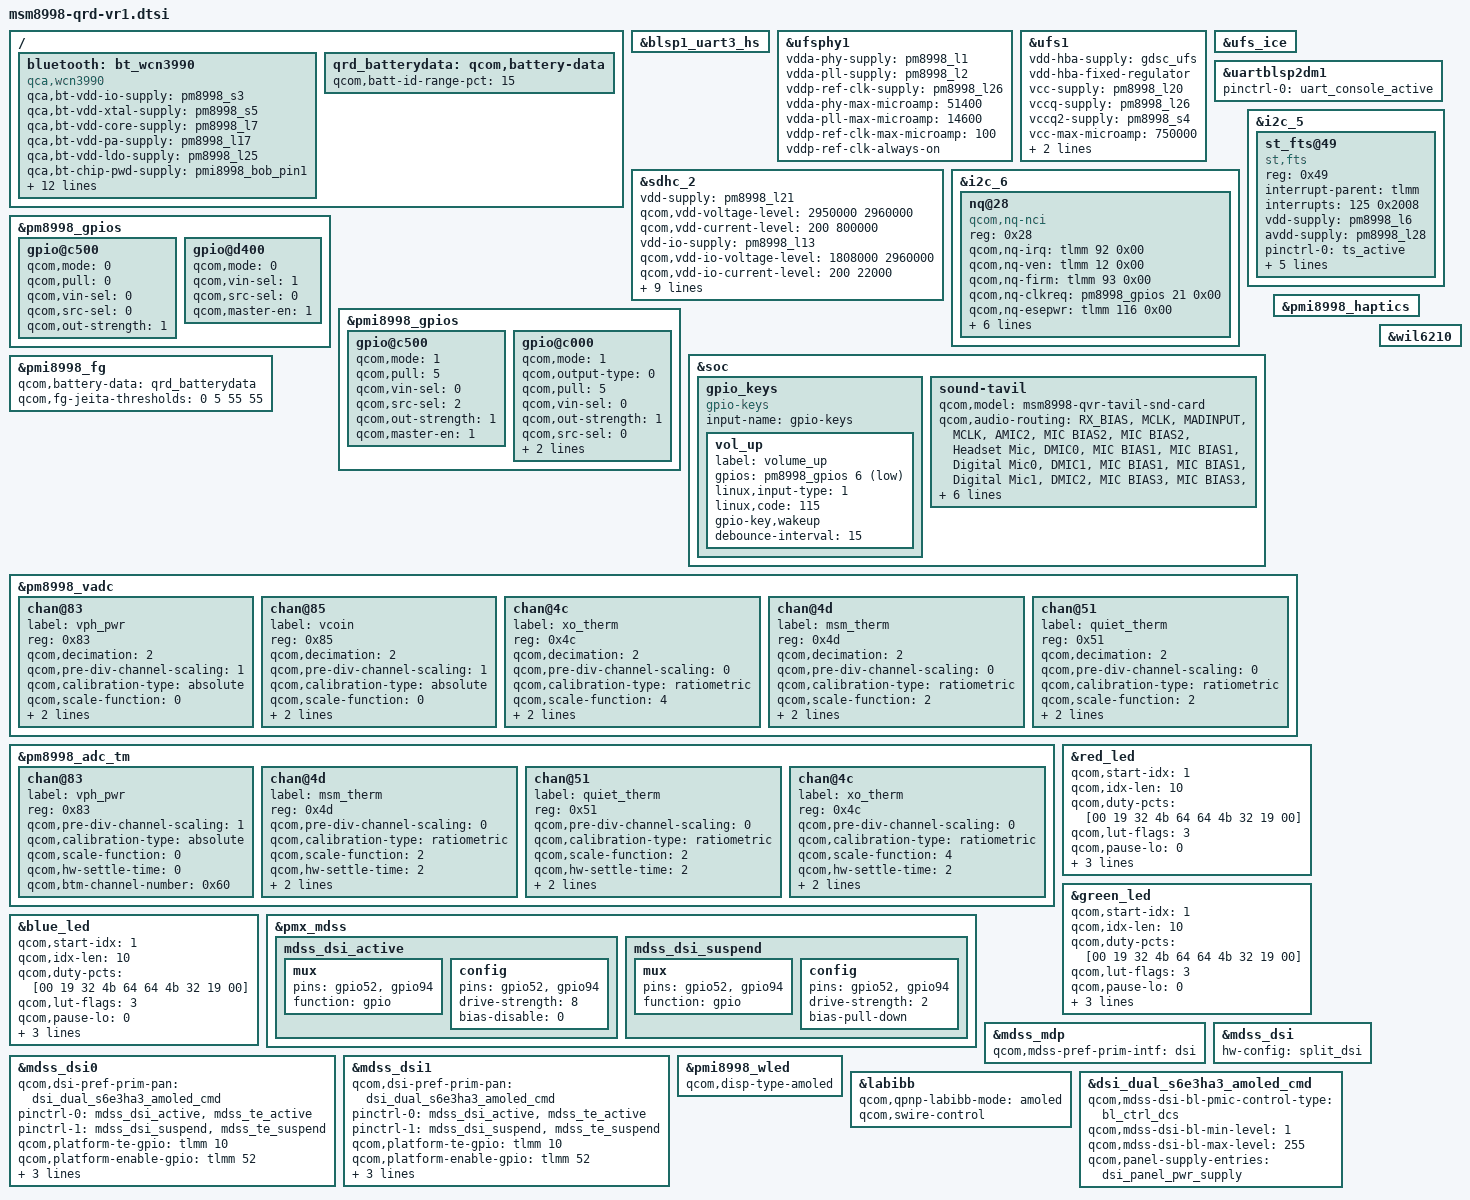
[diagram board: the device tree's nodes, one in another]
/* Copyright (c) 2016-2017, The Linux Foundation. All rights reserved.
 *
 * This program is free software; you can redistribute it and/or modify
 * it under the terms of the GNU General Public License version 2 and
 * only version 2 as published by the Free Software Foundation.
 *
 * This program is distributed in the hope that it will be useful,
 * but WITHOUT ANY WARRANTY; without even the implied warranty of
 * MERCHANTABILITY or FITNESS FOR A PARTICULAR PURPOSE.  See the
 * GNU General Public License for more details.
 */

#include <dt-bindings/interrupt-controller/irq.h>
#include "msm8998-pinctrl.dtsi"
#include "msm8998-camera-sensor-qrd-vr1.dtsi"

/ {
	bluetooth: bt_wcn3990 {
		compatible = "qca,wcn3990";
		qca,bt-vdd-io-supply = <&pm8998_s3>;
		qca,bt-vdd-xtal-supply = <&pm8998_s5>;
		qca,bt-vdd-core-supply = <&pm8998_l7>;
		qca,bt-vdd-pa-supply = <&pm8998_l17>;
		qca,bt-vdd-ldo-supply = <&pm8998_l25>;
		qca,bt-chip-pwd-supply = <&pmi8998_bob_pin1>;
		clocks = <&clock_gcc clk_rf_clk2_pin>;
		clock-names = "rf_clk2";

		qca,bt-vdd-io-voltage-level = <1352000 1352000>;
		qca,bt-vdd-xtal-voltage-level = <2040000 2040000>;
		qca,bt-vdd-core-voltage-level = <1800000 1800000>;
		qca,bt-vdd-pa-voltage-level = <1304000 1304000>;
		qca,bt-vdd-ldo-voltage-level = <3312000 3312000>;
		qca,bt-chip-pwd-voltage-level = <3600000 3600000>;

		qca,bt-vdd-io-current-level = <1>; /* LPM/PFM */
		qca,bt-vdd-xtal-current-level = <1>; /* LPM/PFM */
		qca,bt-vdd-core-current-level = <1>; /* LPM/PFM */
		qca,bt-vdd-pa-current-level = <1>; /* LPM/PFM */
		qca,bt-vdd-ldo-current-level = <1>; /* LPM/PFM */
	};
};

&blsp1_uart3_hs {
	status = "ok";
};

&ufsphy1 {
	vdda-phy-supply = <&pm8998_l1>;
	vdda-pll-supply = <&pm8998_l2>;
	vddp-ref-clk-supply = <&pm8998_l26>;
	vdda-phy-max-microamp = <51400>;
	vdda-pll-max-microamp = <14600>;
	vddp-ref-clk-max-microamp = <100>;
	vddp-ref-clk-always-on;
	status = "ok";
};

&ufs1 {
	vdd-hba-supply = <&gdsc_ufs>;
	vdd-hba-fixed-regulator;
	vcc-supply = <&pm8998_l20>;
	vccq-supply = <&pm8998_l26>;
	vccq2-supply = <&pm8998_s4>;
	vcc-max-microamp = <750000>;
	vccq-max-microamp = <560000>;
	vccq2-max-microamp = <750000>;
	status = "ok";
};

&ufs_ice {
	status = "ok";
};

&sdhc_2 {
	vdd-supply = <&pm8998_l21>;
	qcom,vdd-voltage-level = <2950000 2960000>;
	qcom,vdd-current-level = <200 800000>;

	vdd-io-supply = <&pm8998_l13>;
	qcom,vdd-io-voltage-level = <1808000 2960000>;
	qcom,vdd-io-current-level = <200 22000>;

	pinctrl-names = "active", "sleep";
	pinctrl-0 = <&sdc2_clk_on  &sdc2_cmd_on &sdc2_data_on &sdc2_cd_on>;
	pinctrl-1 = <&sdc2_clk_off &sdc2_cmd_off &sdc2_data_off &sdc2_cd_off>;

	qcom,clk-rates = <400000 20000000 25000000
				50000000 100000000 200000000>;
	qcom,bus-speed-mode = "SDR12", "SDR25", "SDR50", "DDR50", "SDR104";

	cd-gpios = <&tlmm 95 0x0>;

	status = "ok";
};

&uartblsp2dm1 {
	status = "ok";
	pinctrl-names = "default";
	pinctrl-0 = <&uart_console_active>;
};

&i2c_6 { /* BLSP1 QUP6 (NFC) */
	status = "okay";
	nq@28 {
		compatible = "qcom,nq-nci";
		reg = <0x28>;
		qcom,nq-irq = <&tlmm 92 0x00>;
		qcom,nq-ven = <&tlmm 12 0x00>;
		qcom,nq-firm = <&tlmm 93 0x00>;
		qcom,nq-clkreq = <&pm8998_gpios 21 0x00>;
		qcom,nq-esepwr = <&tlmm 116 0x00>;
		interrupt-parent = <&tlmm>;
		qcom,clk-src = "BBCLK3";
		interrupts = <92 0>;
		interrupt-names = "nfc_irq";
		pinctrl-names = "nfc_active", "nfc_suspend";
		pinctrl-0 = <&nfc_int_active &nfc_enable_active>;
		pinctrl-1 = <&nfc_int_suspend &nfc_enable_suspend>;
		clocks = <&clock_gcc clk_ln_bb_clk3_pin>;
		clock-names = "ref_clk";
	};
};

&pm8998_gpios {
	/* GPIO 6 for Vol+ Key */
	gpio@c500 {
		status = "okay";
		qcom,mode = <0>;
		qcom,pull = <0>;
		qcom,vin-sel = <0>;
		qcom,src-sel = <0>;
		qcom,out-strength = <1>;
	};

	/* GPIO 21 (NFC_CLK_REQ) */
	gpio@d400 {
		qcom,mode = <0>;
		qcom,vin-sel = <1>;
		qcom,src-sel = <0>;
		qcom,master-en = <1>;
		status = "okay";
	};
};

&pmi8998_gpios {
	/* GPIO 6 for the internal QNOVO discharge FET control signal */
	gpio@c500 {
		status = "okay";
		qcom,mode = <1>;
		qcom,pull = <5>;
		qcom,vin-sel = <0>;
		qcom,src-sel = <2>;
		qcom,out-strength = <1>;
		qcom,master-en = <1>;
	};
};

&i2c_5 {
	status = "okay";
	st_fts@49 {
		compatible = "st,fts";
		reg = <0x49>;
		interrupt-parent = <&tlmm>;
		interrupts = <125 0x2008>;
		vdd-supply = <&pm8998_l6>;
		avdd-supply = <&pm8998_l28>;
		pinctrl-names = "pmx_ts_active", "pmx_ts_suspend";
		pinctrl-0 = <&ts_active>;
		pinctrl-1 = <&ts_int_suspend &ts_reset_suspend>;
		st,irq-gpio = <&tlmm 125 0x2008>;
		st,reset-gpio = <&tlmm 89 0x00>;
		st,regulator_dvdd = "vdd";
		st,regulator_avdd = "avdd";
	};
};

&soc {
	gpio_keys {
		compatible = "gpio-keys";
		input-name = "gpio-keys";
		status = "okay";

		vol_up {
			label = "volume_up";
			gpios = <&pm8998_gpios 6 0x1>;
			linux,input-type = <1>;
			linux,code = <115>;
			gpio-key,wakeup;
			debounce-interval = <15>;
		};
	};

	sound-tavil {
		qcom,model = "msm8998-qvr-tavil-snd-card";
		qcom,audio-routing =
			"RX_BIAS", "MCLK",
			"MADINPUT", "MCLK",
			"AMIC2", "MIC BIAS2",
			"MIC BIAS2", "Headset Mic",
			"DMIC0", "MIC BIAS1",
			"MIC BIAS1", "Digital Mic0",
			"DMIC1", "MIC BIAS1",
			"MIC BIAS1", "Digital Mic1",
			"DMIC2", "MIC BIAS3",
			"MIC BIAS3", "Digital Mic2",
			"DMIC4", "MIC BIAS4",
			"MIC BIAS4", "Digital Mic4",
			"SpkrLeft IN", "SPK1 OUT";

		qcom,msm-mbhc-hphl-swh = <1>;
		/delete-property/ qcom,us-euro-gpios;
		/delete-property/ qcom,hph-en0-gpio;
		/delete-property/ qcom,hph-en0-gpio;

		qcom,wsa-max-devs = <1>;
		qcom,wsa-devs = <&wsa881x_0211>, <&wsa881x_0213>;
		qcom,wsa-aux-dev-prefix = "SpkrLeft", "SpkrLeft";
	};
};

/{
	qrd_batterydata: qcom,battery-data {
		qcom,batt-id-range-pct = <15>;
		#include "fg-gen3-batterydata-qrd-skuk-4v4-3000mah.dtsi"
	};
};

&pmi8998_fg {
	qcom,battery-data = <&qrd_batterydata>;
	qcom,fg-jeita-thresholds = <0 5 55 55>;
};

&pmi8998_haptics {
	status = "okay";
};

&pm8998_vadc {
	chan@83 {
		label = "vph_pwr";
		reg = <0x83>;
		qcom,decimation = <2>;
		qcom,pre-div-channel-scaling = <1>;
		qcom,calibration-type = "absolute";
		qcom,scale-function = <0>;
		qcom,hw-settle-time = <0>;
		qcom,fast-avg-setup = <0>;
	};

	chan@85 {
		label = "vcoin";
		reg = <0x85>;
		qcom,decimation = <2>;
		qcom,pre-div-channel-scaling = <1>;
		qcom,calibration-type = "absolute";
		qcom,scale-function = <0>;
		qcom,hw-settle-time = <0>;
		qcom,fast-avg-setup = <0>;
	};

	chan@4c {
		label = "xo_therm";
		reg = <0x4c>;
		qcom,decimation = <2>;
		qcom,pre-div-channel-scaling = <0>;
		qcom,calibration-type = "ratiometric";
		qcom,scale-function = <4>;
		qcom,hw-settle-time = <2>;
		qcom,fast-avg-setup = <0>;
	};

	chan@4d {
		label = "msm_therm";
		reg = <0x4d>;
		qcom,decimation = <2>;
		qcom,pre-div-channel-scaling = <0>;
		qcom,calibration-type = "ratiometric";
		qcom,scale-function = <2>;
		qcom,hw-settle-time = <2>;
		qcom,fast-avg-setup = <0>;
	};

	chan@51 {
		label = "quiet_therm";
		reg = <0x51>;
		qcom,decimation = <2>;
		qcom,pre-div-channel-scaling = <0>;
		qcom,calibration-type = "ratiometric";
		qcom,scale-function = <2>;
		qcom,hw-settle-time = <2>;
		qcom,fast-avg-setup = <0>;
	};
};

&pm8998_adc_tm {
	chan@83 {
		label = "vph_pwr";
		reg = <0x83>;
		qcom,pre-div-channel-scaling = <1>;
		qcom,calibration-type = "absolute";
		qcom,scale-function = <0>;
		qcom,hw-settle-time = <0>;
		qcom,btm-channel-number = <0x60>;
	};

	chan@4d {
		label = "msm_therm";
		reg = <0x4d>;
		qcom,pre-div-channel-scaling = <0>;
		qcom,calibration-type = "ratiometric";
		qcom,scale-function = <2>;
		qcom,hw-settle-time = <2>;
		qcom,btm-channel-number = <0x68>;
		qcom,thermal-node;
	};

	chan@51 {
		label = "quiet_therm";
		reg = <0x51>;
		qcom,pre-div-channel-scaling = <0>;
		qcom,calibration-type = "ratiometric";
		qcom,scale-function = <2>;
		qcom,hw-settle-time = <2>;
		qcom,btm-channel-number = <0x70>;
		qcom,thermal-node;
	};

	chan@4c {
		label = "xo_therm";
		reg = <0x4c>;
		qcom,pre-div-channel-scaling = <0>;
		qcom,calibration-type = "ratiometric";
		qcom,scale-function = <4>;
		qcom,hw-settle-time = <2>;
		qcom,btm-channel-number = <0x78>;
		qcom,thermal-node;
	};
};

&red_led {
	/delete-property/ linux,default-trigger;
	qcom,start-idx = <1>;
	qcom,idx-len = <10>;
	qcom,duty-pcts = [00 19 32 4b 64
			64 4b 32 19 00];
	qcom,lut-flags = <3>;
	qcom,pause-lo = <0>;
	qcom,pause-hi = <0>;
	qcom,ramp-step-ms = <255>;
	qcom,use-blink;
};

&green_led {
	/delete-property/ linux,default-trigger;
	qcom,start-idx = <1>;
	qcom,idx-len = <10>;
	qcom,duty-pcts = [00 19 32 4b 64
			64 4b 32 19 00];
	qcom,lut-flags = <3>;
	qcom,pause-lo = <0>;
	qcom,pause-hi = <0>;
	qcom,ramp-step-ms = <255>;
	qcom,use-blink;
};

&blue_led {
	/delete-property/ linux,default-trigger;
	qcom,start-idx = <1>;
	qcom,idx-len = <10>;
	qcom,duty-pcts = [00 19 32 4b 64
			64 4b 32 19 00];
	qcom,lut-flags = <3>;
	qcom,pause-lo = <0>;
	qcom,pause-hi = <0>;
	qcom,ramp-step-ms = <255>;
	qcom,use-blink;
};

&pmx_mdss {
	mdss_dsi_active: mdss_dsi_active {
		mux {
			pins = "gpio52", "gpio94";
			function = "gpio";
		};

		config {
			pins = "gpio52", "gpio94";
			drive-strength = <8>; /* 8 mA */
			bias-disable = <0>; /* no pull */
		};
	};

	mdss_dsi_suspend: mdss_dsi_suspend {
		mux {
			pins = "gpio52", "gpio94";
			function = "gpio";
		};

		config {
			pins = "gpio52", "gpio94";
			drive-strength = <2>; /* 2 mA */
			bias-pull-down; /* pull down */
		};
	};
};

&mdss_mdp {
	qcom,mdss-pref-prim-intf = "dsi";
};

&mdss_dsi {
	hw-config = "split_dsi";
};

&mdss_dsi0 {
	qcom,dsi-pref-prim-pan = <&dsi_dual_s6e3ha3_amoled_cmd>;
	pinctrl-names = "mdss_default", "mdss_sleep";
	pinctrl-0 = <&mdss_dsi_active &mdss_te_active>;
	pinctrl-1 = <&mdss_dsi_suspend &mdss_te_suspend>;
	qcom,platform-te-gpio = <&tlmm 10 0>;
	qcom,platform-enable-gpio = <&tlmm 52 0>;
	qcom,platform-reset-gpio = <&tlmm 94 0>;
	qcom,platform-bklight-en-gpio = <&pmi8998_gpios 1 0>;
	qcom,platform-bklight-en-gpio-invert;
};

&mdss_dsi1 {
	qcom,dsi-pref-prim-pan = <&dsi_dual_s6e3ha3_amoled_cmd>;
	pinctrl-names = "mdss_default", "mdss_sleep";
	pinctrl-0 = <&mdss_dsi_active &mdss_te_active>;
	pinctrl-1 = <&mdss_dsi_suspend &mdss_te_suspend>;
	qcom,platform-te-gpio = <&tlmm 10 0>;
	qcom,platform-enable-gpio = <&tlmm 52 0>;
	qcom,platform-reset-gpio = <&tlmm 94 0>;
	qcom,platform-bklight-en-gpio = <&pmi8998_gpios 1 0>;
	qcom,platform-bklight-en-gpio-invert;
};

&pmi8998_wled {
	qcom,disp-type-amoled;
};

&labibb {
	status = "ok";
	qcom,qpnp-labibb-mode = "amoled";
	qcom,swire-control;
};

&pmi8998_gpios {
	/* GPIO 1 for WLED power enable */
	gpio@c000 {
		qcom,mode = <1>;
		qcom,output-type = <0>;
		qcom,pull = <5>;
		qcom,vin-sel = <0>;
		qcom,out-strength = <1>;
		qcom,src-sel = <0>;
		qcom,invert = <0>;
		qcom,master-en = <1>;
		status = "okay";
	};
};

&dsi_dual_s6e3ha3_amoled_cmd {
	qcom,mdss-dsi-bl-pmic-control-type = "bl_ctrl_dcs";
	qcom,mdss-dsi-bl-min-level = <1>;
	qcom,mdss-dsi-bl-max-level = <255>;
	qcom,panel-supply-entries = <&dsi_panel_pwr_supply>;
};

&wil6210 {
	status = "ok";
};
